# R9A09G057H register map
Vendor: Renesas Electronics; File version: 1.0
Registers are 32-bit, read-write, no defined reset value unless marked. A register's access mark holds for its fields unless they carry their own. Offsets are from the block's base; [hi:lo] are bit positions; {n}, {i} and the like mark numbered series.

## R_SCIFA0 — IO define file for scifa.
Base 0x11C01400
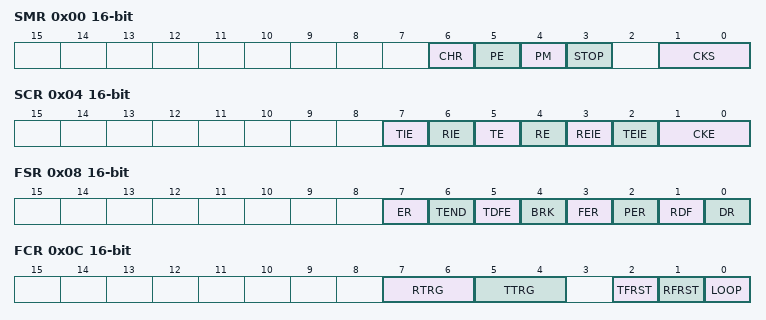
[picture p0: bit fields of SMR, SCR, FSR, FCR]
0x00 SMR 16-bit
  [6] CHR, [5] PE, [4] PM, [3] STOP, [1:0] CKS
0x02 MDDR 8-bit
0x02 BRR 8-bit
0x04 SCR 16-bit
  [7] TIE, [6] RIE, [5] TE, [4] RE, [3] REIE, [2] TEIE, [1:0] CKE
0x06 FTDR 8-bit wo
0x08 FSR 16-bit
  [7] ER, [6] TEND, [5] TDFE, [4] BRK, [3] FER ro, [2] PER ro, [1] RDF, [0] DR
0x0A FRDR 8-bit ro
0x0C FCR 16-bit
  [7:6] RTRG, [5:4] TTRG, [2] TFRST, [1] RFRST, [0] LOOP
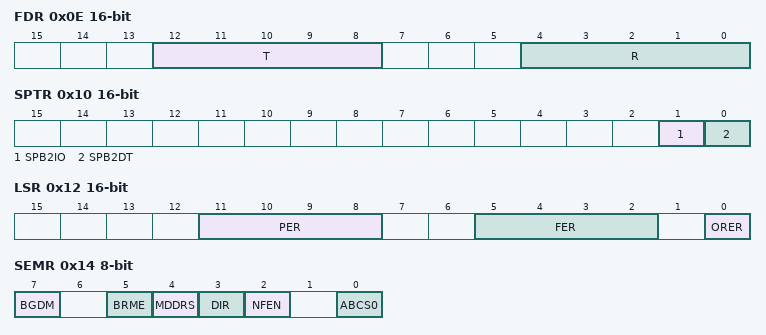
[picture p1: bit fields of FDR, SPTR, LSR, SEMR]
0x0E FDR 16-bit ro
  [12:8] T, [4:0] R
0x10 SPTR 16-bit
  [1] SPB2IO, [0] SPB2DT
0x12 LSR 16-bit
  [11:8] PER ro, [5:2] FER ro, [0] ORER
0x14 SEMR 8-bit
  [7] BGDM, [5] BRME, [4] MDDRS, [3] DIR, [2] NFEN, [0] ABCS0
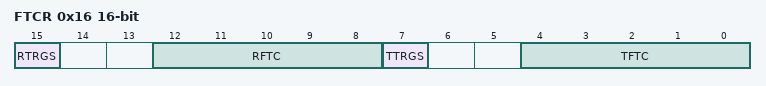
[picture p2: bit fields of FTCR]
0x16 FTCR 16-bit
  [15] RTRGS, [12:8] RFTC, [7] TTRGS, [4:0] TFTC

## R_SPI_B0 — IO define file for spi.
Base 0x12800000
Same registers: R_SPI_B1 0x12800400, R_SPI_B2 0x12800800
0x00 SPDR
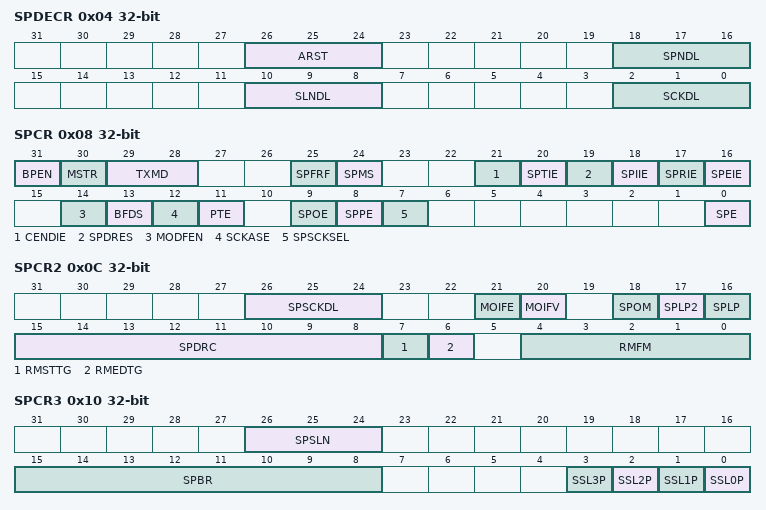
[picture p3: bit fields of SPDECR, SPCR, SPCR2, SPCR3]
0x04 SPDECR
  [26:24] ARST, [18:16] SPNDL, [10:8] SLNDL, [2:0] SCKDL
0x08 SPCR
  [31] BPEN, [30] MSTR, [29:28] TXMD, [25] SPFRF, [24] SPMS, [21] CENDIE, [20] SPTIE, [19] SPDRES, [18] SPIIE, [17] SPRIE, [16] SPEIE, [14] MODFEN, [13] BFDS, [12] SCKASE, [11] PTE, [9] SPOE, [8] SPPE, [7] SPSCKSEL, [0] SPE
0x0C SPCR2
  [26:24] SPSCKDL, [21] MOIFE, [20] MOIFV, [18] SPOM, [17] SPLP2, [16] SPLP, [15:8] SPDRC, [7] RMSTTG wo, [6] RMEDTG wo, [4:0] RMFM
0x10 SPCR3
  [26:24] SPSLN, [15:8] SPBR, [n] SSL{n}P (n=0..3)
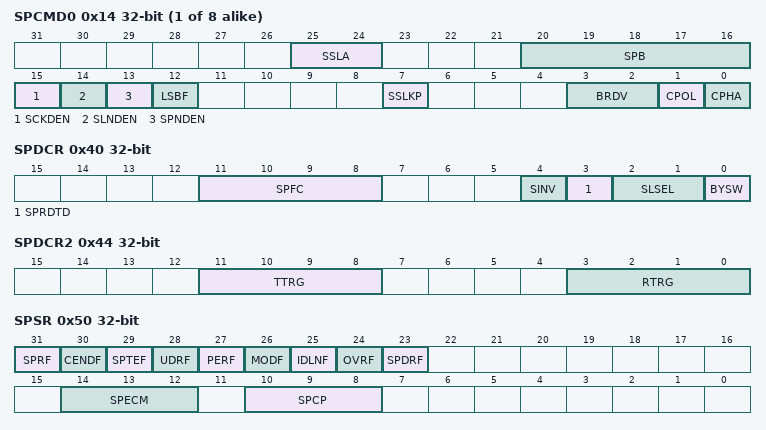
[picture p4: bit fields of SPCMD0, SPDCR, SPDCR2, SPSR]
{0x14+4i} SPCMD{i} (i=0..7)
  [25:24] SSLA, [20:16] SPB, [15] SCKDEN, [14] SLNDEN, [13] SPNDEN, [12] LSBF, [7] SSLKP, [3:2] BRDV, [1] CPOL, [0] CPHA
0x40 SPDCR
  [11:8] SPFC, [4] SINV, [3] SPRDTD, [2:1] SLSEL, [0] BYSW
0x44 SPDCR2
  [11:8] TTRG, [3:0] RTRG
0x50 SPSR ro
  [31] SPRF, [30] CENDF, [29] SPTEF, [28] UDRF, [27] PERF, [26] MODF, [25] IDLNF, [24] OVRF, [23] SPDRF, [14:12] SPECM, [10:8] SPCP
0x58 SPTFSR ro
  [4:0] TFDN
0x5C SPRFSR ro
  [4:0] RFDN
0x60 SPPSR ro
  [0] SPEPS
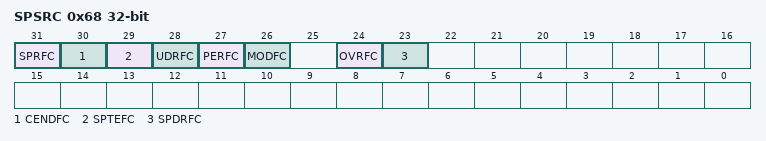
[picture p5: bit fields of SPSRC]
0x68 SPSRC
  [31] SPRFC wo, [30] CENDFC wo, [29] SPTEFC wo, [28] UDRFC wo, [27] PERFC wo, [26] MODFC wo, [24] OVRFC wo, [23] SPDRFC wo
0x6C SPFCR
  [0] SPFRST wo

## R_SPIBSC — IO define file for spibsc.
Base 0x40060000
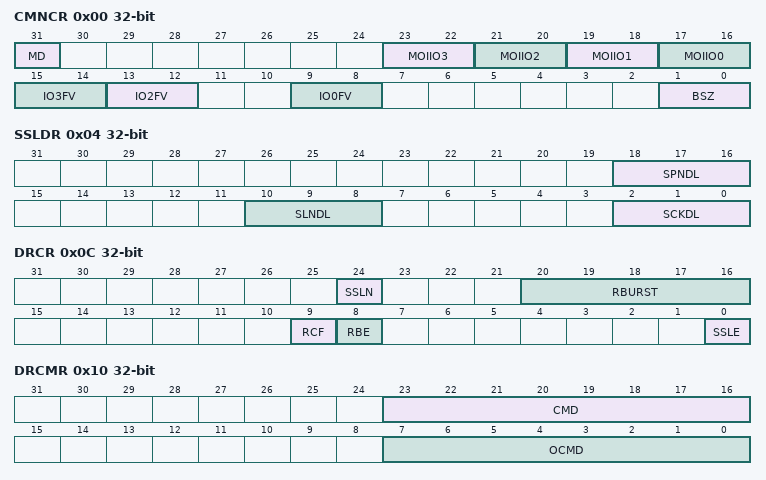
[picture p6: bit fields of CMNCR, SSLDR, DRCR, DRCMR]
0x00 CMNCR
  [31] MD, [2n+17:2n+16] MOIIO{n} (n=0..3), [15:14] IO3FV, [13:12] IO2FV, [9:8] IO0FV, [1:0] BSZ
0x04 SSLDR
  [18:16] SPNDL, [10:8] SLNDL, [2:0] SCKDL
0x0C DRCR
  [24] SSLN wo, [20:16] RBURST, [9] RCF wo, [8] RBE, [0] SSLE
0x10 DRCMR
  [23:16] CMD, [7:0] OCMD
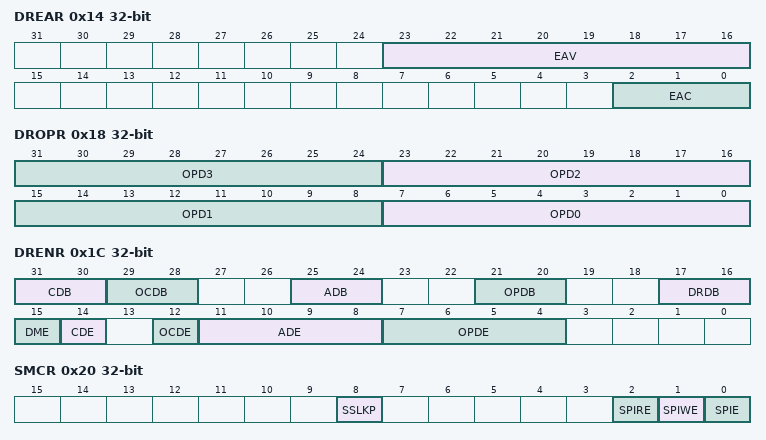
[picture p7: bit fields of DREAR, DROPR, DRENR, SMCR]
0x14 DREAR
  [23:16] EAV, [2:0] EAC
0x18 DROPR
  [8n+7:8n] OPD{n} (n=0..3)
0x1C DRENR
  [31:30] CDB, [29:28] OCDB, [25:24] ADB, [21:20] OPDB, [17:16] DRDB, [15] DME, [14] CDE, [12] OCDE, [11:8] ADE, [7:4] OPDE
0x20 SMCR
  [8] SSLKP, [2] SPIRE, [1] SPIWE, [0] SPIE wo
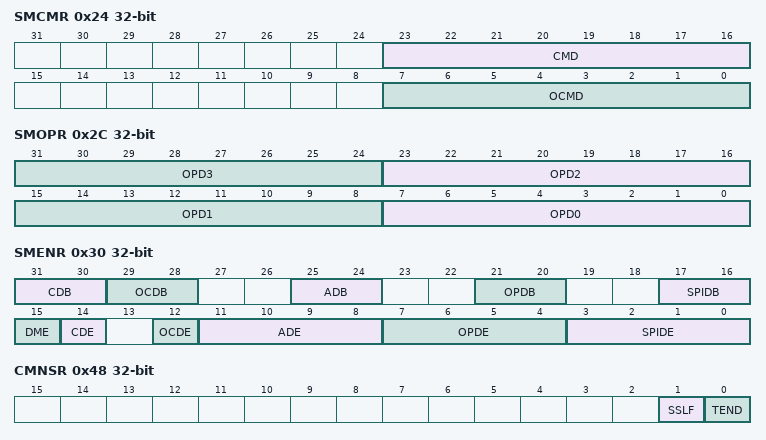
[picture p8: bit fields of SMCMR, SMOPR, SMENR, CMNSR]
0x24 SMCMR
  [23:16] CMD, [7:0] OCMD
0x28 SMADR
  [31:0] ADR
0x2C SMOPR
  [8n+7:8n] OPD{n} (n=0..3)
0x30 SMENR
  [31:30] CDB, [29:28] OCDB, [25:24] ADB, [21:20] OPDB, [17:16] SPIDB, [15] DME, [14] CDE, [12] OCDE, [11:8] ADE, [7:4] OPDE, [3:0] SPIDE
0x38 L 16-bit ro
0x38 LL 8-bit ro
0x38 SMRDR0 ro
  [31:0] RDATA0
0x39 LH 8-bit ro
0x3A H 16-bit ro
0x3A HL 8-bit ro
0x3B HH 8-bit ro
0x3C L_1 16-bit ro
0x3C LL_1 8-bit ro
0x3C SMRDR1 ro
  [31:0] RDATA1
0x3D LH_1 8-bit ro
0x3E H_1 16-bit ro
0x3E HL_1 8-bit ro
0x3F HH_1 8-bit ro
0x40 L_2 16-bit
0x40 LL_2 8-bit
0x40 SMWDR0
  [31:0] WDATA0
0x41 LH_2 8-bit
0x42 H_2 16-bit
0x42 HL_2 8-bit
0x43 HH_2 8-bit
0x44 L_3 16-bit
0x44 LL_3 8-bit
0x44 SMWDR1
  [31:0] WDATA1
0x45 LH_3 8-bit
0x46 H_3 16-bit
0x46 HL_3 8-bit
0x47 HH_3 8-bit
0x48 CMNSR ro
  [1] SSLF, [0] TEND
0x58 DRDMCR
  [4:0] DMCYC
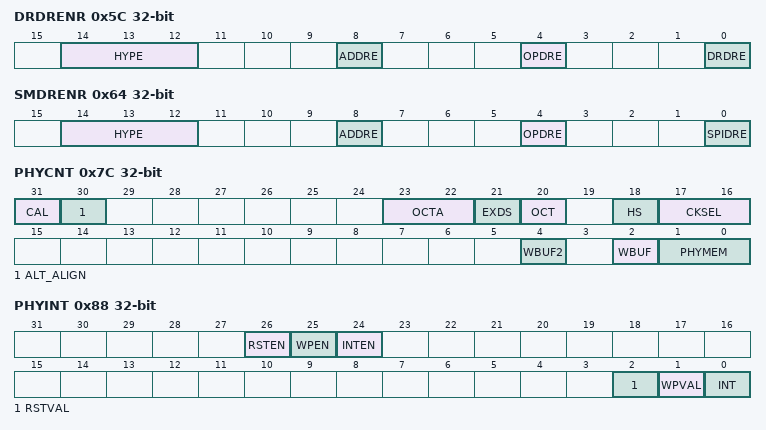
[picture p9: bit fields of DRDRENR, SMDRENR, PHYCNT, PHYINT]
0x5C DRDRENR
  [14:12] HYPE, [8] ADDRE, [4] OPDRE, [0] DRDRE
0x60 SMDMCR
  [4:0] DMCYC
0x64 SMDRENR
  [14:12] HYPE, [8] ADDRE, [4] OPDRE, [0] SPIDRE
0x70 PHYADJ1
  [31:0] ADJ1
0x74 PHYADJ2
  [31:0] ADJ2
0x7C PHYCNT
  [31] CAL wo, [30] ALT_ALIGN, [23:22] OCTA, [21] EXDS, [20] OCT, [18] HS, [17:16] CKSEL, [4] WBUF2, [2] WBUF, [1:0] PHYMEM
0x80 PHYOFFSET1
  [29:28] DDRTMG
0x84 PHYOFFSET2
  [10:8] OCTTMG
0x88 PHYINT
  [26] RSTEN, [25] WPEN, [24] INTEN, [2] RSTVAL, [1] WPVAL, [0] INT ro
